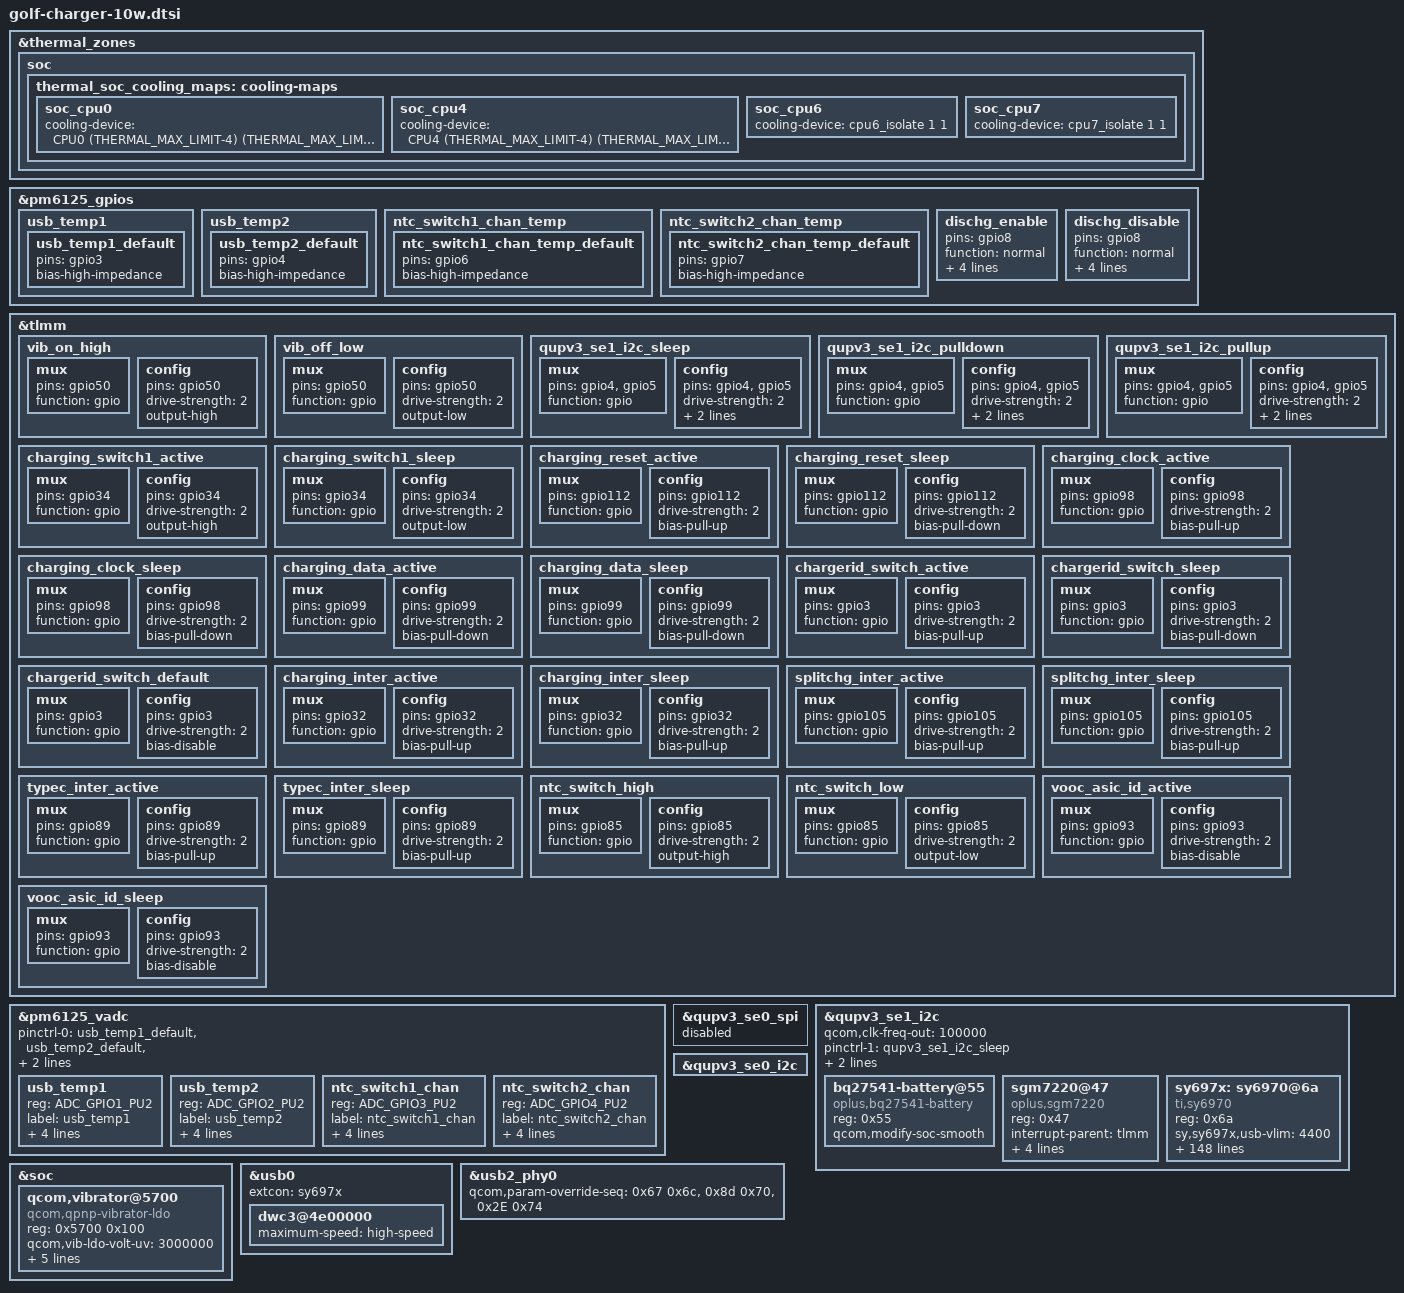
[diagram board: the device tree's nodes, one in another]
/*
&smb1355 {
	/delete-property/ pinctrl-names;
	/delete-property/ pinctrl-0;
	/delete-property/ interrupt-parent;
	/delete-property/ interrupts;
	/delete-property/ status;

	status = "disabled";
};

&smb1355_charger {
	/delete-property/ pinctrl-names;
	/delete-property/ pinctrl-0;
	/delete-property/ qcom,parallel-mode;
	/delete-property/ qcom,disable-ctm;
	/delete-property/ qcom,hw-die-temp-mitigation;
	/delete-property/ status;

	status = "disabled";
};


&dsi_td4330_truly_v2_video {
	/delete-property/ qcom,platform-bklight-en-gpio;
};

&dsi_td4330_truly_v2_cmd {
	/delete-property/ qcom,platform-bklight-en-gpio;
};

&sde_dsi {
	/delete-property/ lab-supply;
	/delete-property/ ibb-supply;
};
*/
&thermal_zones {
	soc {
		thermal_soc_cooling_maps: cooling-maps {
			soc_cpu0 {
				//trip = <&pmi632_low_soc>;
				cooling-device =
					<&CPU0 (THERMAL_MAX_LIMIT-4)
						(THERMAL_MAX_LIMIT-4)>;
			};

			soc_cpu4 {
				//trip = <&pmi632_low_soc>;
				cooling-device =
					<&CPU4 (THERMAL_MAX_LIMIT-4)
						(THERMAL_MAX_LIMIT-4)>;
			};

			soc_cpu6 {
				//trip = <&pmi632_low_soc>;
				cooling-device = <&cpu6_isolate 1 1>;
			};

			soc_cpu7 {
				//trip = <&pmi632_low_soc>;
				cooling-device = <&cpu7_isolate 1 1>;
			};
		};
	};
};

/*split charger dts config*/
&pm6125_gpios {
	usb_temp1 {
		usb_temp1_default: usb_temp1_default {
			pins = "gpio3";
			bias-high-impedance;
		};
	};

	usb_temp2 {
		usb_temp2_default: usb_temp2_default {
			pins = "gpio4";
			bias-high-impedance;
		};
	};

	ntc_switch1_chan_temp {
		ntc_switch1_chan_temp_default: ntc_switch1_chan_temp_default {
			pins = "gpio6";
			bias-high-impedance;
		};
	};

	ntc_switch2_chan_temp {
		ntc_switch2_chan_temp_default: ntc_switch2_chan_temp_default {
			pins = "gpio7";
			bias-high-impedance;
		};
	};

	dischg_enable: dischg_enable {
		pins = "gpio8";
		function = "normal";
		power-source = <0>;
		output-high;
		input-disable;
		qcom,drive-strength = <2>;
	};

	dischg_disable: dischg_disable {
		pins = "gpio8";
		function = "normal";
		power-source = <0>;
		output-low;
		input-disable;
		qcom,drive-strength = <2>;
	};
	/delete-node/ camera_therm;
	/delete-node/ emmc_therm;
};

&tlmm {
			vib_on_high: vib_on_high {
				mux {
					pins = "gpio50";
					function = "gpio";
				};

				config {
					pins = "gpio50";
					drive-strength = <2>;
					output-high;
				};
			};
			vib_off_low: vib_off_low {
				mux {
					pins = "gpio50";
					function = "gpio";
				};

				config {
					pins = "gpio50";
					drive-strength = <2>;
					output-low;
				};
			};

			qupv3_se1_i2c_sleep: qupv3_se1_i2c_sleep {
				mux {
					pins = "gpio4", "gpio5";
					function = "gpio";
				};

				config {
					pins = "gpio4", "gpio5";
					drive-strength = <2>;
					bias-no-pull;
					output-high;
				};
			};

			qupv3_se1_i2c_pulldown: qupv3_se1_i2c_pulldown {
				mux {
					pins = "gpio4", "gpio5";
					function = "gpio";
				};

				config {
					pins = "gpio4", "gpio5";
					drive-strength = <2>;
					bias-pull-down;
					output-low;
				};
			};

			qupv3_se1_i2c_pullup: qupv3_se1_i2c_pullup {
				mux {
					pins = "gpio4", "gpio5";
					function = "gpio";
				};

				config {
					pins = "gpio4", "gpio5";
					drive-strength = <2>;
					bias-pull-up;
					input-enable;
				};
			};

			charging_switch1_active: charging_switch1_active {
				mux {
					pins = "gpio34";
					function = "gpio";
				};

				config {
					pins = "gpio34";
					drive-strength = <2>;
					output-high;
				};
			};

			charging_switch1_sleep: charging_switch1_sleep {
				mux {
					pins = "gpio34";
					function = "gpio";
				};

				config {
					pins = "gpio34";
					drive-strength = <2>;
					output-low;
				};
			};

			charging_reset_active: charging_reset_active {
				mux {
					pins = "gpio112";
					function = "gpio";
				};

				config {
					pins = "gpio112";
					drive-strength = <2>;
					bias-pull-up;
				};
			};

			charging_reset_sleep: charging_reset_sleep {
				mux {
					pins = "gpio112";
					function = "gpio";
				};

				config {
					pins = "gpio112";
					drive-strength = <2>;
					bias-pull-down;
				};
			};

			charging_clock_active: charging_clock_active {
				mux {
					pins = "gpio98";
					function = "gpio";
				};

				config {
					pins = "gpio98";
					drive-strength = <2>;
					bias-pull-up;
				};
			};

			charging_clock_sleep: charging_clock_sleep {
				mux {
					pins = "gpio98";
					function = "gpio";
				};

				config {
					pins = "gpio98";
					drive-strength = <2>;
					bias-pull-down;
				};
			};

			charging_data_active: charging_data_active {
				mux {
					pins = "gpio99";
					function = "gpio";
				};

				config {
					pins = "gpio99";
					drive-strength = <2>;
					bias-pull-down;
				};
			};

			charging_data_sleep: charging_data_sleep {
				mux {
					pins = "gpio99";
					function = "gpio";
				};

				config {
					pins = "gpio99";
					drive-strength = <2>;
					bias-pull-down;
				};
			};

			chargerid_switch_active: chargerid_switch_active {
				mux {
					pins = "gpio3";
					function = "gpio";
				};

				config {
					pins = "gpio3";
					drive-strength = <2>;
					bias-pull-up;
				};
			};

			chargerid_switch_sleep: chargerid_switch_sleep {
				mux {
					pins = "gpio3";
					function = "gpio";
				};

				config {
					pins = "gpio3";
					drive-strength = <2>;
					bias-pull-down;
				};
			};

			chargerid_switch_default: chargerid_switch_default {
				mux {
					pins = "gpio3";
					function = "gpio";
				};

				config {
					pins = "gpio3";
					drive-strength = <2>;
					bias-disable; /* NO PULL */
				};
			};

             charging_inter_active: charging_inter_active {
                     mux {
                             pins = "gpio32";
                             function = "gpio";
                     };

                     config {
                             pins = "gpio32";
                             drive-strength = <2>;
                             bias-pull-up;
                     };
             };

             charging_inter_sleep: charging_inter_sleep {
                     mux {
                             pins = "gpio32";
                             function = "gpio";
                     };

                     config {
                             pins = "gpio32";
                             drive-strength = <2>;
                             bias-pull-up;
                     };
            };

             /*split_chg*/
             splitchg_inter_active: splitchg_inter_active {
                     mux {
                             pins = "gpio105";
                             function = "gpio";
                     };

                     config {
                             pins = "gpio105";
                             drive-strength = <2>;
                             bias-pull-up;
                     };
             };

             splitchg_inter_sleep: splitchg_inter_sleep {
                     mux {
                             pins = "gpio105";
                             function = "gpio";
                     };

                     config {
                             pins = "gpio105";
                             drive-strength = <2>;
                             bias-pull-up;
                     };
            };

             typec_inter_active: typec_inter_active {
                     mux {
                             pins = "gpio89";
                             function = "gpio";
                     };

                     config {
                             pins = "gpio89";
                             drive-strength = <2>;
                             bias-pull-up;
                     };
             };

             typec_inter_sleep: typec_inter_sleep {
                     mux {
                             pins = "gpio89";
                             function = "gpio";
                     };

                     config {
                             pins = "gpio89";
                             drive-strength = <2>;
                             bias-pull-up;
                     };
            };

			ntc_switch_high: ntc_switch_high {
				mux {
					pins = "gpio85";
					function = "gpio";
				};

				config {
					pins = "gpio85";
					drive-strength = <2>;
					output-high;
				};
			};

			ntc_switch_low: ntc_switch_low {
				mux {
					pins = "gpio85";
					function = "gpio";
				};

				config {
					pins = "gpio85";
					drive-strength = <2>;
					output-low;
				};
			};

			vooc_asic_id_active: vooc_asic_id_active {
				mux {
					pins = "gpio93";
					function = "gpio";
				};

				config {
					pins = "gpio93";
					drive-strength = <2>;
					bias-disable; /* NO PULL */
				};
			};

			vooc_asic_id_sleep: vooc_asic_id_sleep {
				mux {
					pins = "gpio93";
					function = "gpio";
				};

				config {
					pins = "gpio93";
					drive-strength = <2>;
					bias-disable; /* NO PULL */
				};
			};
};

&pm6125_vadc {
	pinctrl-0 = <&usb_temp1_default &usb_temp2_default &ntc_switch1_chan_temp_default &ntc_switch2_chan_temp_default>;

	usb_temp1 {
		reg = <ADC_GPIO1_PU2>;
		label = "usb_temp1";
		qcom,ratiometric;
		qcom,hw-settle-time = <200>;
		qcom,pre-scaling = <1 1>;
		qcom,scale-fn-type = <ADC_SCALE_HW_CALIB_DEFAULT>;
	};

	usb_temp2 {
		reg = <ADC_GPIO2_PU2>;
		label = "usb_temp2";
		qcom,ratiometric;
		qcom,hw-settle-time = <200>;
		qcom,pre-scaling = <1 1>;
		qcom,scale-fn-type = <ADC_SCALE_HW_CALIB_DEFAULT>;
	};

	ntc_switch1_chan {
		reg = <ADC_GPIO3_PU2>;
		label = "ntc_switch1_chan";
		qcom,ratiometric;
		qcom,hw-settle-time = <200>;
		qcom,pre-scaling = <1 1>;
		qcom,scale-fn-type = <ADC_SCALE_HW_CALIB_DEFAULT>;
	};

	ntc_switch2_chan {
		reg = <ADC_GPIO4_PU2>;
		label = "ntc_switch2_chan";
		qcom,ratiometric;
		qcom,hw-settle-time = <200>;
		qcom,pre-scaling = <1 1>;
		qcom,scale-fn-type = <ADC_SCALE_HW_CALIB_DEFAULT>;
	};
	/delete-node/ camera_flash_therm;
	/delete-node/ emmc_ufs_therm;
};

&qupv3_se0_spi {
	status = "disabled";
};

&qupv3_se1_i2c {
	status = "okay";
	qcom,clk-freq-out = <100000>;
	pinctrl-names = "default", "sleep", "pulldown", "pullup";
	pinctrl-1 = <&qupv3_se1_i2c_sleep>;
	pinctrl-2 = <&qupv3_se1_i2c_pulldown>;
	pinctrl-3 = <&qupv3_se1_i2c_pullup>;
	bq27541-battery@55 {
		status = "okay";
		compatible = "oplus,bq27541-battery";
		reg = <0x55>;
		qcom,modify-soc-smooth;
		//qcom,battery-full-param;//only for wite battery full param in guage dirver probe on 7250 platform
	};

	sgm7220@47 {
		status = "okay";
		compatible = "oplus,sgm7220";
		reg = <0x47>;
		interrupt-parent = <&tlmm>;
		interrupts = <89 0>;
		interrupt-names = "sgm7220_int_irq";
		sgm7220,irq_gpio = <&tlmm 89 0x8008>;
		//sgm7220,reset-gpio = <&tlmm 12 0x0>;

		//typec irq
		pinctrl-names = "typec_inter_active", "typec_inter_sleep";
		pinctrl-0 = <&typec_inter_active>;
		pinctrl-1 = <&typec_inter_sleep>;
	};

	sy697x: sy6970@6a {
			status = "okay";
			compatible = "ti,sy6970";
			reg = <0x6a>;

			sy,sy697x,usb-vlim =<4400>;
			sy,sy697x,precharge-current = <256>;
			sy,sy697x,termination-current = <250>;
			sy,sy697x,boost-current = <1200>;
			sy,sy697x,charge-detect-enable;

			/*oplus charger config*/
			//test_bob-supply = <&pm8150a_bob>;
			qcom,usb-icl-ua = <3000000>;
			qcom,fcc-max-ua = <3000000>;
			//qcom,fv-max-uv = <4373000>;
			//qcom,hvdcp-disable;
			qcom,sec-charger-config = <0>;
			qcom,float-option = <1>;

			//for oplus chg framework:
			qcom,input_current_charger_ma = <2000>;
			qcom,pd_input_current_charger_ma = <3000>;
			qcom,input_current_usb_ma = <500>;

			qcom,input_current_led_ma = <1200>;
			qcom,input_current_led_ma_high = <1200>;
			qcom,input_current_led_ma_warm = <1500>;
			qcom,input_current_led_ma_normal = <2000>;

			qcom,input_current_camera_ma = <1200>;
			qcom,input_current_cdp_ma = <1500>;
			//qcom,input_current_led_ma_overtemp = <900>;
			qcom,overtemp_bat_decidegc = <350>;
			qcom,iterm_disabled = <0>;
			sw_full_count = <25>;
			qcom,iterm_ma = <254>;
			qcom,recharge-mv = <100>;
			qcom,batt_capacity_mah = <4890>;/*typical capacity*/
			//qcom,batt_capacity_mah = <4880>; /*rated capacity*/

			qcom,removed_bat_decidegc = <190>;	/* < -19C */

			qcom,cold_bat_decidegc = <20>;		/* -2C ~ 0C */
			qcom,temp_cold_vfloat_mv = <3980>;
			qcom,temp_cold_fastchg_current_ma = <500>;

			qcom,little_cold_bat_decidegc = <0>;	/* 0C ~ 5C */
			qcom,temp_little_cold_vfloat_mv = <4435>;
			qcom,temp_little_cold_fastchg_current_ma_high = <2200>;
			qcom,temp_little_cold_fastchg_current_ma_low = <1400>;
			qcom,pd_temp_little_cold_fastchg_current_ma_high = <3300>;
			qcom,pd_temp_little_cold_fastchg_current_ma_low = <2300>; //1.5C 2318
			qcom,temp_little_cold_fastchg_current_ma = <2200>;

			qcom,cool_bat_decidegc = <50>;		/* 5C~12C */
			qcom,temp_cool_vfloat_mv = <4435>;
			qcom,temp_cool_fastchg_current_ma_high = <2200>;
			qcom,temp_cool_fastchg_current_ma_low = <2200>;
			qcom,pd_temp_cool_fastchg_current_ma_high = <3300>;
			qcom,pd_temp_cool_fastchg_current_ma_low = <3200>; // 1.5C  3200

			qcom,little_cool_bat_decidegc = <120>;	/*12C~16C*/
			qcom,temp_little_cool_vfloat_mv = <4435>;
			qcom,temp_little_cool_fastchg_current_ma = <2200>;
			qcom,pd_temp_little_cool_fastchg_current_ma = <3300>;

			qcom,normal_bat_decidegc = <160>;	/*16C~44C*/
			qcom,temp_normal_fastchg_current_ma = <2200>;
			qcom,pd_temp_normal_fastchg_current_ma = <3300>;
			qcom,temp_normal_vfloat_mv = <4435>;

			qcom,warm_bat_decidegc = <450>;		/*44C~53C*/ /*8pin Bat Vooc project need add 3 degree C*/
			qcom,temp_warm_vfloat_mv = <4130>;
			qcom,temp_warm_fastchg_current_ma = <1400>;
			qcom,pd_temp_warm_fastchg_current_ma = <1300>;
			qcom,temp_warm_fastchg_current_ma_led_on = <500>;

			qcom,hot_bat_decidegc = <530>;

			qcom,non_standard_vfloat_mv = <3980>;
			qcom,non_standard_fastchg_current_ma = <512>;
			qcom,short_c_bat_cv_mv = <4330>;
			qcom,short_c_bat_vfloat_mv = <3800>;
			qcom,short_c_bat_fastchg_current_ma = <512>;

			qcom,cold_vfloat_sw_limit = <3930>;
			qcom,little_cold_vfloat_sw_limit = <4385>;
			qcom,cool_vfloat_sw_limit = <4385>;
			qcom,little_cool_vfloat_sw_limit = <4385>;
			qcom,normal_vfloat_sw_limit = <4385>;
			qcom,warm_vfloat_sw_limit = <4080>;
			qcom,non_standard_vfloat_sw_limit = <4385>;
			qcom,short_c_bat_vfloat_sw_limit = <3750>;

			qcom,max_chg_time_sec = <72000>;
			qcom,charger_hv_thr = <10000>;
			qcom,charger_recv_thr = <5500>;
			qcom,charger_lv_thr = <3400>;
			qcom,vbatt_full_thr = <4400>;
			qcom,vbatt_hv_thr = <4550>;
			qcom,vfloat_step_mv = <8>;
			qcom,non_standard_vfloat_over_sw_limit = <3990>;
			qcom,cold_vfloat_over_sw_limit = <3990>;
			qcom,little_cold_vfloat_over_sw_limit = <4445>;
			qcom,cool_vfloat_over_sw_limit = <4445>;
			qcom,little_cool_vfloat_over_sw_limit = <4445>;
			qcom,normal_vfloat_over_sw_limit = <4445>;
			qcom,warm_vfloat_over_sw_limit = <4140>;

			qcom,vbatt_power_off = <3300>;
			qcom,vbatt_soc_1 = <3410>;
			qcom,soc_to_0_withchg = <3200>;
			qcom,soc_to_0_withoutchg = <3300>;
			qcom,vooc_project = <0>;
			qcom,vbatt_num = <1>;
			//qcom,new_ui_warning_support;
			//qcom,ffc_support;
			//qcom,dual_ffc;
			//qcom,voocphy_support;
			qcom,smart_charging_screenoff;

			qcom,normal_vterm_hw_inc = <18>;
			qcom,non_normal_vterm_hw_inc = <18>;

			qcom,ff1_normal_fastchg_ma = <1500>;
			qcom,ff1_warm_fastchg_ma = <1500>;
			qcom,ff1_exit_step_ma = <550>;
			qcom,ff1_warm_exit_step_ma = <500>;
			qcom,ffc2_normal_fastchg_ma = <1200>;/*12C~35c*/
			qcom,ffc2_temp_warm_decidegc = <350>;
			qcom,ffc2_warm_fastchg_ma = <1300>;/*35C~40c*/
			qcom,ffc2_temp_high_decidegc = <400>;
			qcom,ffc2_temp_low_decidegc = <120>;
			qcom,ffc2_exit_step_ma = <150>;

			qcom,ffc_normal_vfloat_sw_limit = <4475>;
			qcom,ffc_temp_normal_vfloat_mv = <4550>;
			qcom,ffc_normal_vfloat_over_sw_limit = <4550>;

			qcom,default_iterm_ma = <254>;
			qcom,default_temp_normal_fastchg_current_ma = <2200>;
			qcom,default_normal_vfloat_sw_limit = <4385>;
			qcom,default_temp_normal_vfloat_mv = <4435>;
			qcom,default_normal_vfloat_over_sw_limit = <4445>;

			qcom,default_temp_little_cool_fastchg_current_ma = <2200>;
			qcom,default_little_cool_vfloat_sw_limit = <4385>;
			qcom,default_temp_little_cool_vfloat_mv = <4435>;
			qcom,default_little_cool_vfloat_over_sw_limit = <4445>;

			///qcom,offset_temp = <30>;
			//for control:
			//qcom,suspend_after_full;
			qcom,check_batt_full_by_sw;
			qcom,external_gauge;
			qcom,chg_ctrl_by_lcd;
			qcom,chg_ctrl_by_camera;
			qcom,sw_vfloat_over_protect_enable;
			qcom,lpd-disable;

			//qcom,vooc_show_ui_soc_decimal;
			qcom,ui_soc_decimal_speedmin = <20>;//2A

			qcom,chargerid_switch-gpio = <&tlmm 3 0x00>;
			qcom,dischg-gpio = <&pm6125_gpios 8 0x00>;

			//sy697x irq
			qcom,chg_irq_gpio = <&tlmm 105 0x00>;
			interrupt-parent = <&tlmm>;
			interrupts = <105 0>;

			//ntc switch gpio
			qcom,ntc-switch-gpio = <&tlmm 85 0x00>;

			pinctrl-names = "chargerid_switch_active", "chargerid_switch_sleep", "chargerid_switch_default",
							"dischg_enable", "dischg_disable", "splitchg_inter_active", "splitchg_inter_sleep",
							"ntc_switch_high", "ntc_switch_low";

			pinctrl-0 = <&chargerid_switch_active>;
			pinctrl-1 = <&chargerid_switch_sleep>;
			pinctrl-2 = <&chargerid_switch_default>;
			pinctrl-3 = <&dischg_enable>;
			pinctrl-4 = <&dischg_disable>;
			pinctrl-5 = <&splitchg_inter_active>;
			pinctrl-6 = <&splitchg_inter_sleep>;
			pinctrl-7 = <&ntc_switch_high>;
			pinctrl-8 = <&ntc_switch_low>;

			io-channels = <&pm6125_vadc ADC_GPIO1_PU2>,
				<&pm6125_vadc ADC_GPIO2_PU2>,
				<&pm6125_vadc ADC_GPIO3_PU2>,
				<&pm6125_vadc ADC_GPIO4_PU2>;
			io-channel-names = "usb_temp1",
				"usb_temp2",
				"ntc_switch1_chan",
				"ntc_switch2_chan";
			dpdm-supply = <&usb2_phy0>;
	};
};

/*load vibrator for rm pmic*/
&soc {
	qcom,vibrator@5700 {
			compatible = "qcom,qpnp-vibrator-ldo";
			reg = <0x5700 0x100>;
			qcom,vib-ldo-volt-uv = <3000000>;
			qcom,disable-overdrive;
			qcom,vib-type = <1>;	/*0:ldo 1:gpio*/
			status = "okay";

			qcom,vibrator_switch-gpio = <&tlmm 50 0x00>;
			pinctrl-names = "vib_on_high", "vib_off_low";
			pinctrl-0 = <&vib_on_high>;
			pinctrl-1 = <&vib_off_low >;
	};
};

&qupv3_se0_i2c {
	status = "okay";
	//qcom,clk-freq-out = <100000>;

};

&usb0 {
	extcon = <&sy697x>;
	dwc3@4e00000 {
		maximum-speed = "high-speed";
	};
};

&usb2_phy0 {
	qcom,param-override-seq = <0x67 0x6c>, //override_x0
				  <0x8d 0x70>, //override_x1
				  <0x2E 0x74>; //override_x2
};

